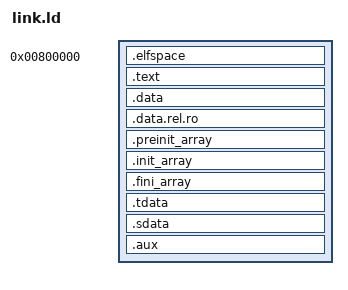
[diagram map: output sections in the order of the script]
OUTPUT_FORMAT("elf64-littleriscv", "elf64-littleriscv",
	      "elf64-littleriscv")
OUTPUT_ARCH(riscv)
SECTIONS
{
  . = 0x00800000;
  .elfspace : { *(.elfspace) }
  _start = .;
  .text : { *(.text) }
  .data : { *(.data) }
  .data.rel.ro : { *(.data.rel.ro) }
  .preinit_array     ALIGN(0x8):
  {
    PROVIDE_HIDDEN (__preinit_array_start = .);
    KEEP (*(.preinit_array*))
    PROVIDE_HIDDEN (__preinit_array_end = .);
  }
  .init_array ALIGN(0x8):
  {
    PROVIDE_HIDDEN (__init_array_start = .);
    KEEP (*(SORT(.init_array.*)))
    KEEP (*(.init_array*))
    PROVIDE_HIDDEN (__init_array_end = .);
  }
  .fini_array ALIGN(0x8):
  {
    PROVIDE_HIDDEN (__fini_array_start = .);
    KEEP (*(SORT(.fini_array.*)))
    KEEP (*(.fini_array*))
    PROVIDE_HIDDEN (__fini_array_end = .);
  }
  .tdata	  ALIGN(0x8):
   {
     PROVIDE_HIDDEN (__tdata_start = .);
     *(.tdata .tdata.* .gnu.linkonce.td.*)
   }
  .sdata          ALIGN(0x8):
  {
    __global_pointer$ = . + 0x800;
    *(.srodata.cst16) *(.srodata.cst8) *(.srodata.cst4) *(.srodata.cst2) *(.srodata .srodata.*)
    *(.sdata .sdata.* .gnu.linkonce.s.*)
  }
  .aux : { *(.aux) }
}
